# D1.pdf register map
Vendor: Allwinner; Series: D1.pdf; File version: 0.1
CPU: XuanTie C906 RISC-V CPU 0, little endian, MPU, FPU, double-precision FPU, 0 interrupt priority bits
Registers are 32-bit, read-write, reset 0x0 unless marked. A register's access mark holds for its fields unless they carry their own. Offsets are from the block's base; [hi:lo] are bit positions; {n}, {i} and the like mark numbered series; 'fields as' and 'values as' point back to an identical list.

## CCU (part 2 of 2)
Base 0x02001000
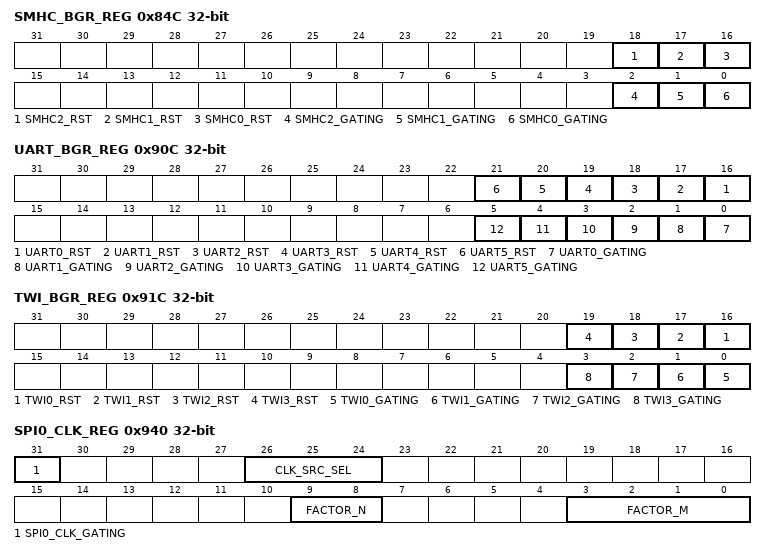
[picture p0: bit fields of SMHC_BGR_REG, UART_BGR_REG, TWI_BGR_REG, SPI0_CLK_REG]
0x84C SMHC_BGR_REG — SMHC Bus Gating Reset Register
  [18] SMHC2_RST — SMHC2 Reset 0: Assert 1: De-assert
    0=Assert; 1=deassert
  [17] SMHC1_RST — SMHC1 Reset 0: Assert 1: De-assert
    0=Assert; 1=deassert
  [16] SMHC0_RST — SMHC0 Reset 0: Assert 1: De-assert
    0=Assert; 1=deassert
  [2] SMHC2_GATING — Gating Clock for SMHC2 0: Mask 1: Pass
    0=Mask; 1=Pass
  [1] SMHC1_GATING — Gating Clock for SMHC1 0: Mask 1: Pass
    0=Mask; 1=Pass
  [0] SMHC0_GATING — Gating Clock for SMHC0 0: Mask 1: Pass
    0=Mask; 1=Pass
0x90C UART_BGR_REG — UART Bus Gating Reset Register
  [n+16] UART{n}_RST (n=0..5) — UART{n} Reset 0: Assert 1: De-assert
    0=Assert; 1=deassert
  [n] UART{n}_GATING (n=0..5) — Gating Clock for UART{n} 0: Mask 1: Pass
    0=Mask; 1=Pass
0x91C TWI_BGR_REG — TWI Bus Gating Reset Register
  [n+16] TWI{n}_RST (n=0..3) — TWI{n} Reset 0: Assert 1: De-assert
    0=Assert; 1=deassert
  [n] TWI{n}_GATING (n=0..3) — Gating Clock for TWI{n} 0: Mask 1: Pass
    0=Mask; 1=Pass
0x940 SPI0_CLK_REG — SPI0 Clock Register
  [31] SPI0_CLK_GATING — Gating Clock 0: Clock is OFF 1: Clock is ON SCLK = Clock Source/M/N.
    0=OFF (Clock is OFF); 1=ON (Clock is ON SCLK = Clock Source/M/N.)
  [26:24] CLK_SRC_SEL — Clock Source Select 000: HOSC 001: PLL_PERI(1X) 010: PLL_PERI(2X) 011: PLL_AUDIO1(DIV2) 100: PLL_AUDIO1(DIV5) Others: Reserved
    0=HOSC; 1=PLL_PERI_openingparen_1X_closingparen_ (PLL_PERI(1X)); 2=PLL_PERI_openingparen_2X_closingparen_ (PLL_PERI(2X)); 3=PLL_AUDIO1_openingparen_DIV2_closingparen_ (PLL_AUDIO1(DIV2)); 4=PLL_AUDIO1_openingparen_DIV5_closingparen_ (PLL_AUDIO1(DIV5))
  [9:8] FACTOR_N — Factor N 00: 1 01: 2 10: 4 11: 8
    0=_1; 1=_2; 2=_4; 3=_8
  [3:0] FACTOR_M — Factor M M= FACTOR_M +1 FACTOR_M is from 0 to 15.
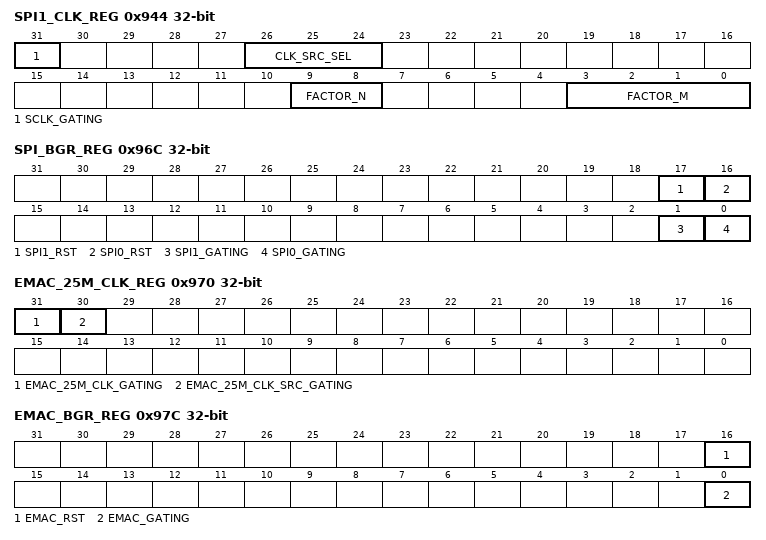
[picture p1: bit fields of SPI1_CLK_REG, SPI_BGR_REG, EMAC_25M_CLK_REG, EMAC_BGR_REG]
0x944 SPI1_CLK_REG — SPI1 Clock Register
  [31] SCLK_GATING — Gating Special Clock 0: Clock is OFF 1: Clock is ON SCLK = Clock Source/M/N.
    values as SPI0_CLK_REG.SPI0_CLK_GATING
  [26:24] CLK_SRC_SEL — Clock Source Select 000: HOSC 001: PLL_PERI(1X) 010: PLL_PERI(2X) 011: PLL_AUDIO1(DIV2) 100: PLL_AUDIO1(DIV5) Others: /
    values as SPI0_CLK_REG.CLK_SRC_SEL
  [9:8] FACTOR_N — Factor N 00: 1 01: 2 10: 4 11: 8
    0=_1; 1=_2; 2=_4; 3=_8
  [3:0] FACTOR_M — Factor M M= FACTOR_M +1 FACTOR_M is from 0 to 15.
0x96C SPI_BGR_REG — SPI Bus Gating Reset Register
  [17] SPI1_RST — SPI1 Reset 0: Assert 1: De-assert
    0=Assert; 1=deassert
  [16] SPI0_RST — SPI0 Reset 0: Assert 1: De-assert
    0=Assert; 1=deassert
  [1] SPI1_GATING — Gating Clock for SPI1 0: Mask 1: Pass
    0=Mask; 1=Pass
  [0] SPI0_GATING — Gating Clock for SPI0 0: Mask 1: Pass
    0=Mask; 1=Pass
0x970 EMAC_25M_CLK_REG — EMAC_25M Clock Register
  [31] EMAC_25M_CLK_GATING — Gating Special Clock 0: Clock is OFF 1: Clock is ON CLK = PLL_PERI(1X)/24 = 25 MHz
    0=OFF (Clock is OFF); 1=ON (Clock is ON CLK = PLL_PERI(1X)/24 = 25 MHz)
  [30] EMAC_25M_CLK_SRC_GATING — Gating the Source Clock of Special Clock It is for low power design. 0: Clock is OFF 1: Clock is ON
    0=OFF (Clock is OFF); 1=ON (Clock is ON)
0x97C EMAC_BGR_REG — EMAC Bus Gating Reset Register
  [16] EMAC_RST — EMAC Reset 0: Assert 1: De-assert
    0=Assert; 1=deassert
  [0] EMAC_GATING — Gating Clock for EMAC 0: Mask 1: Pass
    0=Mask; 1=Pass
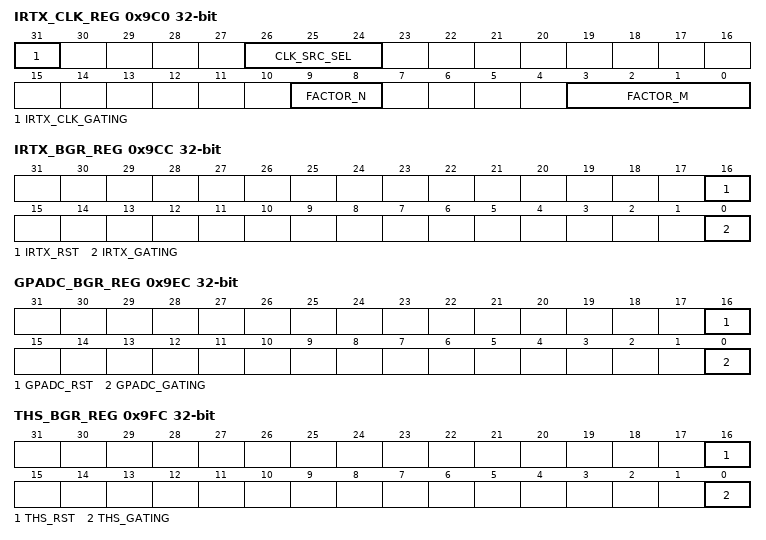
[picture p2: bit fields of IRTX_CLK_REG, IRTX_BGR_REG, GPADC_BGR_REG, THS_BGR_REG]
0x9C0 IRTX_CLK_REG — IRTX Clock Register
  [31] IRTX_CLK_GATING — Gating Clock 0: Clock is OFF 1: Clock is ON IRTX_CLK = Clock Source/M/N.
    0=OFF (Clock is OFF); 1=ON (Clock is ON IRTX_CLK = Clock Source/M/N.)
  [26:24] CLK_SRC_SEL — Clock Source Select 0: HOSC 1: PLL_PERI(1X)
  [9:8] FACTOR_N — Factor N 00: 1 01: 2 10: 4 11: 8
    0=_1; 1=_2; 2=_4; 3=_8
  [3:0] FACTOR_M — Factor M M= FACTOR_M +1 FACTOR_M is from 0 to 15.
0x9CC IRTX_BGR_REG — IRTX Bus Gating Reset Register
  [16] IRTX_RST — IRTX Reset 0: Assert 1: De-assert
    0=Assert; 1=deassert
  [0] IRTX_GATING — Gating Clock for IRTX 0: Mask 1: Pass
    0=Mask; 1=Pass
0x9EC GPADC_BGR_REG — GPADC Bus Gating Reset Register
  [16] GPADC_RST — GPADC Reset 0: Assert 1: De-assert
    0=Assert; 1=deassert
  [0] GPADC_GATING — Gating Clock for GPADC 0: Mask 1: Pass
    0=Mask; 1=Pass
0x9FC THS_BGR_REG — THS Bus Gating Reset Register
  [16] THS_RST — THS Reset 0: Assert 1: De-assert
    0=Assert; 1=deassert
  [0] THS_GATING — Gating Clock for THS 0: Mask 1: Pass
    0=Mask; 1=Pass
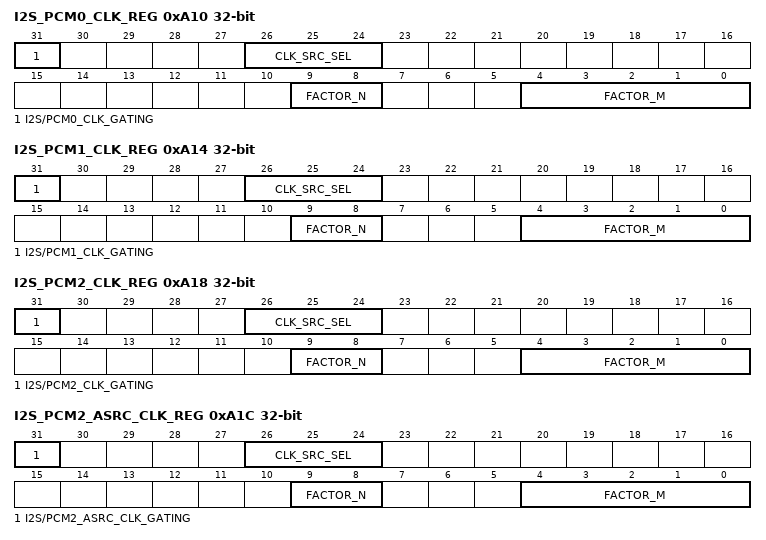
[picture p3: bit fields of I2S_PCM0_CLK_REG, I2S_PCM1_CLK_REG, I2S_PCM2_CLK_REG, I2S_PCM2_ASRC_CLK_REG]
0xA10 I2S_PCM0_CLK_REG
  [31] I2S/PCM0_CLK_GATING — Gating Clock 0: Clock is OFF 1: Clock is ON I2S/PCM0_CLK = Clock Source/M/N.
    0=OFF (Clock is OFF); 1=ON (Clock is ON I2S/PCM0_CLK = Clock Source/M/N.)
  [26:24] CLK_SRC_SEL — Clock Source Select 00: PLL_AUDIO0(1X) 01: PLL_AUDIO0(4X) 10: PLL_AUDIO1(DIV2) 11: PLL_AUDIO1(DIV5)
  [9:8] FACTOR_N — Factor N 00: /1 01: /2 10: /4 11: /8
    0=_slash_1 (/1); 1=_slash_2 (/2); 2=_slash_4 (/4); 3=_slash_8 (/8)
  [4:0] FACTOR_M — Factor M M= FACTOR_M +1 The value of FACTOR_M is from 0 to 31.
0xA14 I2S_PCM1_CLK_REG
  [31] I2S/PCM1_CLK_GATING — Gating Clock 0: Clock is OFF 1: Clock is ON I2S/PCM1_CLK = Clock Source/M/N.
    0=OFF (Clock is OFF); 1=ON (Clock is ON I2S/PCM1_CLK = Clock Source/M/N.)
  [26:24] CLK_SRC_SEL — Clock Source Select 00: PLL_AUDIO0(1X) 01: PLL_AUDIO0(4X) 10: PLL_AUDIO1(DIV2) 11: PLL_AUDIO1(DIV5)
  [9:8] FACTOR_N — Factor N 00: /1 01: /2 10: /4 11: /8
    values as I2S_PCM0_CLK_REG.FACTOR_N
  [4:0] FACTOR_M — Factor M M= FACTOR_M +1 FACTOR_M is from 0 to 31.
0xA18 I2S_PCM2_CLK_REG
  [31] I2S/PCM2_CLK_GATING — Gating Clock 0: Clock is OFF 1: Clock is ON I2S/PCM2_CLK = Clock Source/M/N.
    0=OFF (Clock is OFF); 1=ON (Clock is ON I2S/PCM2_CLK = Clock Source/M/N.)
  [26:24] CLK_SRC_SEL — Clock Source Select 00: PLL_AUDIO0(1X) 01: PLL_AUDIO0(4X) 10: PLL_AUDIO1(DIV2) 11: PLL_AUDIO1(DIV5)
  [9:8] FACTOR_N — Factor N 00: /1 01: /2 10: /4 11: /8
    values as I2S_PCM0_CLK_REG.FACTOR_N
  [4:0] FACTOR_M — Factor M M= FACTOR_M +1 FACTOR_M is from 0 to 31.
0xA1C I2S_PCM2_ASRC_CLK_REG
  [31] I2S/PCM2_ASRC_CLK_GATING — Gating Clock 0: Clock is OFF 1: Clock is ON I2S/PCM2_ASRC_CLK = Clock Source/M/N.
    0=OFF (Clock is OFF); 1=ON (Clock is ON I2S/PCM2_ASRC_CLK = Clock Source/M/N.)
  [26:24] CLK_SRC_SEL — Clock Source Select 00: PLL_AUDIO0(4X) 01: PLL_PERI(1X) 10: PLL_AUDIO1(DIV2) 11: PLL_AUDIO1(DIV5)
  [9:8] FACTOR_N — Factor N 00: /1 01: /2 10: /4 11: /8
    values as I2S_PCM0_CLK_REG.FACTOR_N
  [4:0] FACTOR_M — Factor M M = FACTOR_M +1 FACTOR_M is from 0 to 31.
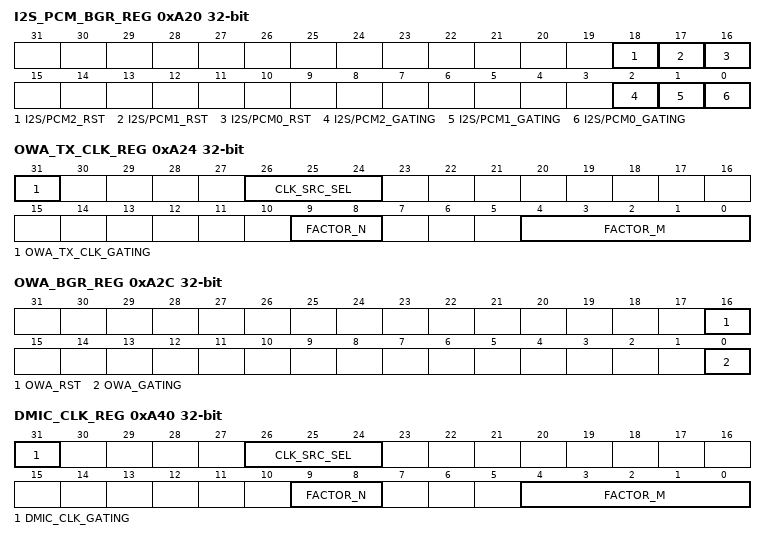
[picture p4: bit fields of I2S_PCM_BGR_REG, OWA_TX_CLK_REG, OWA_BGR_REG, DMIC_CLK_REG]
0xA20 I2S_PCM_BGR_REG
  [18] I2S/PCM2_RST — I2S/PCM2 Reset 0: Assert 1: De-assert
    0=Assert; 1=deassert
  [17] I2S/PCM1_RST — I2S/PCM1 Reset 0: Assert 1: De-assert
    0=Assert; 1=deassert
  [16] I2S/PCM0_RST — I2S/PCM0 Reset 0: Assert 1: De-assert
    0=Assert; 1=deassert
  [2] I2S/PCM2_GATING — Gating Clock for I2S/PCM2 0: Mask 1: Pass
    0=Mask; 1=Pass
  [1] I2S/PCM1_GATING — Gating Clock for I2S/PCM1 0: Mask 1: Pass
    0=Mask; 1=Pass
  [0] I2S/PCM0_GATING — Gating Clock for I2S/PCM0 0: Mask 1: Pass
    0=Mask; 1=Pass
0xA24 OWA_TX_CLK_REG — OWA_TX Clock Register
  [31] OWA_TX_CLK_GATING — Gating Clock 0: Clock is OFF 1: Clock is ON OWA_TX_CLK = Clock Source/M/N.
    0=OFF (Clock is OFF); 1=ON (Clock is ON OWA_TX_CLK = Clock Source/M/N.)
  [26:24] CLK_SRC_SEL — Clock Source Select 00: PLL_AUDIO0(1X) 01: PLL_AUDIO0(4X) 10: PLL_AUDIO1(DIV2) 11: PLL_AUDIO1(DIV5)
  [9:8] FACTOR_N — Factor N 00: /1 01: /2 10: /4 11: /8
    values as I2S_PCM0_CLK_REG.FACTOR_N
  [4:0] FACTOR_M — Factor M M= FACTOR_M +1 FACTOR_M is from 0 to 31.
0xA2C OWA_BGR_REG — OWA Bus Gating Reset Register
  [16] OWA_RST — OWA Reset 0: Assert 1: De-assert
    0=Assert; 1=deassert
  [0] OWA_GATING — Gating Clock for OWA 0: Mask 1: Pass
    0=Mask; 1=Pass
0xA40 DMIC_CLK_REG — DMIC Clock Register
  [31] DMIC_CLK_GATING — Gating Clock 0: Clock is OFF 1: Clock is ON DMIC_CLK = Clock Source/M/N.
    0=OFF (Clock is OFF); 1=ON (Clock is ON DMIC_CLK = Clock Source/M/N.)
  [26:24] CLK_SRC_SEL — Clock Source Select 00: PLL_AUDIO0(1X) 01: PLL_AUDIO1(DIV2) 10: PLL_AUDIO1(DIV5) 11: Reserved
  [9:8] FACTOR_N — Factor N 00: /1 01: /2 10: /4 11: /8
    values as I2S_PCM0_CLK_REG.FACTOR_N
  [4:0] FACTOR_M — Factor M M= FACTOR_M +1 FACTOR_M is from 0 to 31.
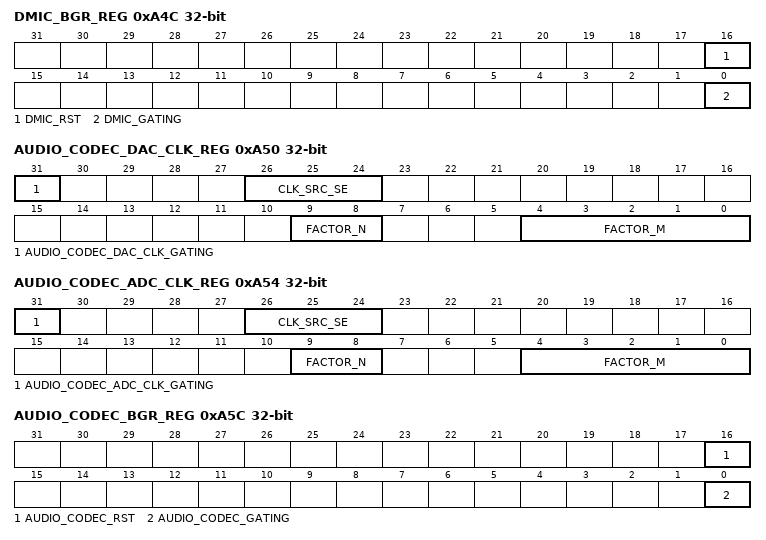
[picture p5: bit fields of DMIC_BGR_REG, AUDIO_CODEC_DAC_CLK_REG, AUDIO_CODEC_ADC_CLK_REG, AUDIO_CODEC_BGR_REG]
0xA4C DMIC_BGR_REG — DMIC Bus Gating Reset Register
  [16] DMIC_RST — DMIC Reset 0: Assert 1: De-assert
    0=Assert; 1=deassert
  [0] DMIC_GATING — Gating Clock for DMIC 0: Mask 1: Pass
    0=Mask; 1=Pass
0xA50 AUDIO_CODEC_DAC_CLK_REG — AUDIO_CODEC_DAC Clock Register
  [31] AUDIO_CODEC_DAC_CLK_GATING — Gating Clock 0: Clock is OFF 1: Clock is ON AUDIO_CODEC_DAC_CLK = Clock Source/M/N.
    0=OFF (Clock is OFF); 1=ON (Clock is ON AUDIO_CODEC_DAC_CLK = Clock Source/M/N.)
  [26:24] CLK_SRC_SE — Clock Source Select 00: PLL_AUDIO0(1X) 01: PLL_AUDIO1(DIV2) 10: PLL_AUDIO1(DIV5)
  [9:8] FACTOR_N — Factor N 00: /1 01: /2 10: /4 11: /8
    values as I2S_PCM0_CLK_REG.FACTOR_N
  [4:0] FACTOR_M — Factor M M= FACTOR_M +1 FACTOR_M is from 0 to 31.
0xA54 AUDIO_CODEC_ADC_CLK_REG — AUDIO_CODEC_ADC Clock Register
  [31] AUDIO_CODEC_ADC_CLK_GATING — Gating Clock 0: Clock is OFF 1: Clock is ON AUDIO_CODEC_ADC_CLK = Clock Source/M/N.
    0=OFF (Clock is OFF); 1=ON (Clock is ON AUDIO_CODEC_ADC_CLK = Clock Source/M/N.)
  [26:24] CLK_SRC_SE — Clock Source Select 00: PLL_AUDIO0(1X) 01: PLL_AUDIO1(DIV2) 10: PLL_AUDIO1(DIV5)
  [9:8] FACTOR_N — Factor N 00: /1 01: /2 10: /4 11: /8
    values as I2S_PCM0_CLK_REG.FACTOR_N
  [4:0] FACTOR_M — Factor M M= FACTOR_M +1 FACTOR_M is from 0 to 31.
0xA5C AUDIO_CODEC_BGR_REG — AUDIO_CODEC Bus Gating Reset Register
  [16] AUDIO_CODEC_RST — AUDIO_CODEC Reset 0: Assert 1: De-assert
    0=Assert; 1=deassert
  [0] AUDIO_CODEC_GATING — Gating Clock for AUDIO_CODEC 0: Mask 1: Pass
    0=Mask; 1=Pass
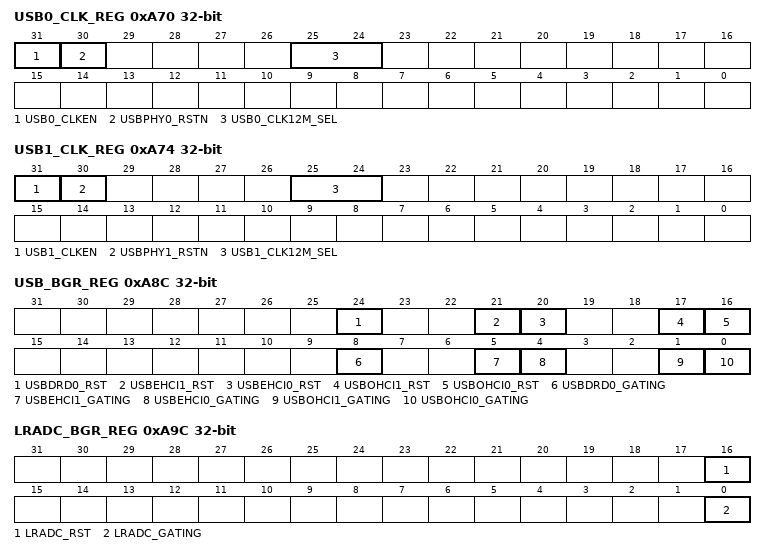
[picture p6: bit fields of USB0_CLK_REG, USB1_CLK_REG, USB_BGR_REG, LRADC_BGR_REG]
0xA70 USB0_CLK_REG — USB0 Clock Register
  [31] USB0_CLKEN — Gating Special Clock for OHCI0 0: Clock is OFF 1: Clock is ON
    0=OFF (Clock is OFF); 1=ON (Clock is ON)
  [30] USBPHY0_RSTN — USB PHY0 Reset 0: Assert 1: De-assert
    0=Assert; 1=deassert
  [25:24] USB0_CLK12M_SEL — OHCI0 12M Source Select 00: 12M divided from 48 MHz 01: 12M divided from 24 MHz 10: RTC_32K 11: /
0xA74 USB1_CLK_REG — USB1 Clock Register
  [31] USB1_CLKEN — Gating Special Clock for OHCI1 0: Clock is OFF 1: Clock is ON
    0=OFF (Clock is OFF); 1=ON (Clock is ON)
  [30] USBPHY1_RSTN — USB PHY1 Reset 0: Assert 1: De-assert
    0=Assert; 1=deassert
  [25:24] USB1_CLK12M_SEL — OHCI0 12M Source Select 00: 12M divided from 48 MHz 01: 12M divided from 24 MHz 10: RTC_32K 11: /
0xA8C USB_BGR_REG — USB Bus Gating Reset Register
  [24] USBDRD0_RST — USBDRD0 Reset 0: Assert 1: De-assert
    0=Assert; 1=deassert
  [21] USBEHCI1_RST — USBEHCI1 Reset 0: Assert 1: De-assert
    0=Assert; 1=deassert
  [20] USBEHCI0_RST — USBEHCI0 Reset 0: Assert 1: De-assert
    0=Assert; 1=deassert
  [17] USBOHCI1_RST — USBOHCI1 Reset 0: Assert 1: De-assert
    0=Assert; 1=deassert
  [16] USBOHCI0_RST — USBOHCI0 Reset 0: Assert 1: De-assert
    0=Assert; 1=deassert
  [8] USBDRD0_GATING — Gating Clock for USBDRD0 0: Mask 1: Pass
    0=Mask; 1=Pass
  [5] USBEHCI1_GATING — Gating Clock for USBEHCI1 0: Mask 1: Pass
    0=Mask; 1=Pass
  [4] USBEHCI0_GATING — Gating Clock for USBEHCI0 0: Mask 1: Pass
    0=Mask; 1=Pass
  [1] USBOHCI1_GATING — Gating Clock for USBOHCI1 0: Mask 1: Pass
    0=Mask; 1=Pass
  [0] USBOHCI0_GATING — Gating Clock for USBOHCI0 0: Mask 1: Pass
    0=Mask; 1=Pass
0xA9C LRADC_BGR_REG
  [16] LRADC_RST — LRADC Reset 0: Assert 1: De-assert
    0=Assert; 1=deassert
  [0] LRADC_GATING — Gating Clock for LRADC 0: Mask 1: Pass
    0=Mask; 1=Pass
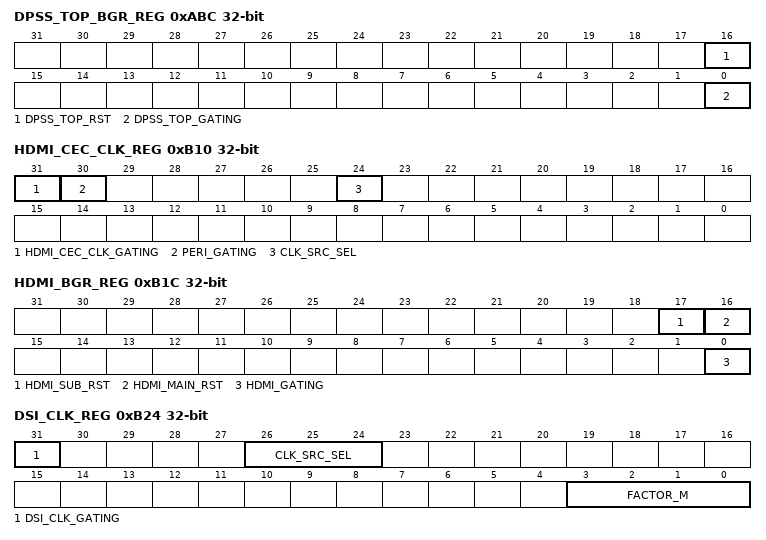
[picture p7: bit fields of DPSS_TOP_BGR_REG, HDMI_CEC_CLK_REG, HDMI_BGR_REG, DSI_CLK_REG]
0xABC DPSS_TOP_BGR_REG — DPSS_TOP Bus Gating Reset Register
  [16] DPSS_TOP_RST — DPSS_TOP Reset 0: Assert 1: De-assert
    0=Assert; 1=deassert
  [0] DPSS_TOP_GATING — Gating Clock for DPSS_TOP 0: Mask 1: Pass
    0=Mask; 1=Pass
0xB04 HDMI_24M_CLK_REG — HDMI_24M Clock Register
  [31] HDMI_24M_CLK_GATING — Gating Clock 0: Clock is OFF 1: Clock is ON HDMI_24M_CLK = HOSC
    0=OFF (Clock is OFF); 1=ON (Clock is ON HDMI_24M_CLK = HOSC)
0xB10 HDMI_CEC_CLK_REG — HDMI CEC Clock Register
  [31] HDMI_CEC_CLK_GATING — Gating Clock 0: Clock is OFF 1: Clock is ON HDMI_CEC_CLK = Clock Source.
    0=OFF (Clock is OFF); 1=ON (Clock is ON HDMI_CEC_CLK = Clock Source.)
  [30] PERI_GATING — Gating PERIPLL Clock 0: Clock is OFF 1: Clock is ON
    0=OFF (Clock is OFF); 1=ON (Clock is ON)
  [24] CLK_SRC_SEL — Clock Source Select 0: CLK32K 1: HDMI_CEC_CLK32K, PLL_PERI(2X)/36621 = 32.768 kHz 1X:/
    0=CLK32K; 1=HDMI_CEC_CLK32K (HDMI_CEC_CLK32K, PLL_PERI(2X)/36621 = 32.768 kHz)
0xB1C HDMI_BGR_REG — HDMI Bus Gating Reset Register
  [17] HDMI_SUB_RST — HDMI_SUB Reset 0: Assert 1: De-assert
    0=Assert; 1=deassert
  [16] HDMI_MAIN_RST — HDMI_MAIN Reset 0: Assert 1: De-assert
    0=Assert; 1=deassert
  [0] HDMI_GATING — Gating Clock for HDMI 0: Mask 1: Pass
    0=Mask; 1=Pass
0xB24 DSI_CLK_REG — DSI Clock Register
  [31] DSI_CLK_GATING — Gating Clock 0: Clock is OFF 1: Clock is ON DSI_CLK = Clock Source/M.
    0=OFF (Clock is OFF); 1=ON (Clock is ON DSI_CLK = Clock Source/M.)
  [26:24] CLK_SRC_SEL — Clock Source Select 000: HOSC 001: PLL_PERI(1X) 010: PLL_VIDEO0(2X) 011: PLL_VIDEO1(2X) 100: PLL_AUDIO1(DIV2)
    0=HOSC; 1=PLL_PERI_openingparen_1X_closingparen_ (PLL_PERI(1X)); 2=PLL_VIDEO0_openingparen_2X_closingparen_ (PLL_VIDEO0(2X)); 3=PLL_VIDEO1_openingparen_2X_closingparen_ (PLL_VIDEO1(2X)); 4=PLL_AUDIO1_openingparen_DIV2_closingparen_ (PLL_AUDIO1(DIV2))
  [3:0] FACTOR_M — Factor M M= FACTOR_M +1 FACTOR_M is from 0 to 15.
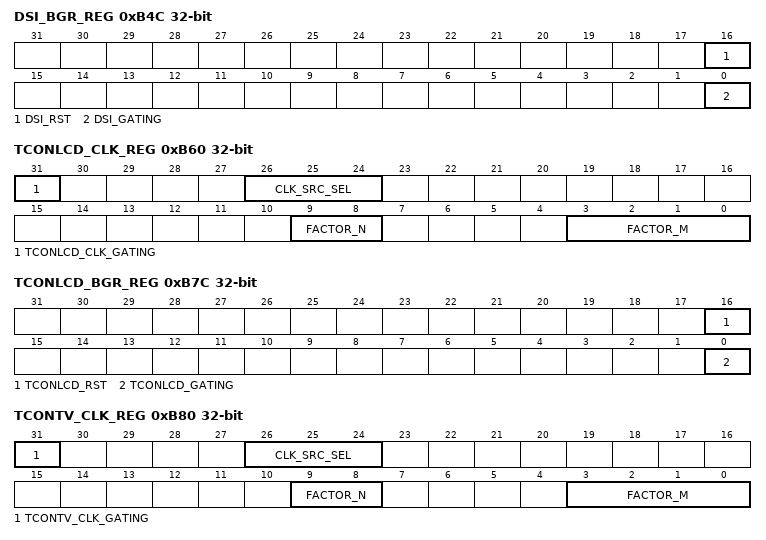
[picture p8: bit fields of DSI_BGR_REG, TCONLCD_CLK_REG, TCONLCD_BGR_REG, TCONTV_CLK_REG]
0xB4C DSI_BGR_REG — DSI Bus Gating Reset Register
  [16] DSI_RST — DSI Reset 0: Assert 1: De-assert
    0=Assert; 1=deassert
  [0] DSI_GATING — Gating Clock for DSI 0: Mask 1: Pass
    0=Mask; 1=Pass
0xB60 TCONLCD_CLK_REG — TCONLCD Clock Register
  [31] TCONLCD_CLK_GATING — Gating Clock 0: Clock is OFF 1: Clock is ON TCONLCD_CLK = Clock Source/M/N.
    0=OFF (Clock is OFF); 1=ON (Clock is ON TCONLCD_CLK = Clock Source/M/N.)
  [26:24] CLK_SRC_SEL — Clock Source Select 000: PLL_VIDEO0(1X) 001: PLL_VIDEO0(4X) 010: PLL_VIDEO1(1X) 011: PLL_VIDEO1(4X) 100: PLL_PERI(2X) 101: PLL_AUDIO1(DIV2)
    0=PLL_VIDEO0_openingparen_1X_closingparen_ (PLL_VIDEO0(1X)); 1=PLL_VIDEO0_openingparen_4X_closingparen_ (PLL_VIDEO0(4X)); 2=PLL_VIDEO1_openingparen_1X_closingparen_ (PLL_VIDEO1(1X)); 3=PLL_VIDEO1_openingparen_4X_closingparen_ (PLL_VIDEO1(4X)); 4=PLL_PERI_openingparen_2X_closingparen_ (PLL_PERI(2X)); 5=PLL_AUDIO1_openingparen_DIV2_closingparen_ (PLL_AUDIO1(DIV2))
  [9:8] FACTOR_N — Factor N 00: 1 01: 2 10: 4 11: 8
    0=_1; 1=_2; 2=_4; 3=_8
  [3:0] FACTOR_M — Factor M M= FACTOR_M +1. FACTOR_M is from 0 to 15.
0xB7C TCONLCD_BGR_REG — TCONLCD Bus Gating Reset Register
  [16] TCONLCD_RST — TCON LCD Reset 0: Assert 1: DE-assert
    0=Assert; 1=deassert
  [0] TCONLCD_GATING — Gating Clock for TCON LCD 0: Mask 1: Pass
    0=Mask; 1=Pass
0xB80 TCONTV_CLK_REG — TCONTV Clock Register
  [31] TCONTV_CLK_GATING — Gating Clock 0: Clock is OFF 1: Clock is ON TCONTV_CLK = Clock Source/M/N.
    0=OFF (Clock is OFF); 1=ON (Clock is ON TCONTV_CLK = Clock Source/M/N.)
  [26:24] CLK_SRC_SEL — Clock Source Select 000: PLL_VIDEO0(1X) 001: PLL_VIDEO0(4X) 010: PLL_VIDEO1(1X) 011: PLL_VIDEO1(4X) 100: PLL_PERI(2X) 101: PLL_AUDIO1(DIV2)
    values as TCONLCD_CLK_REG.CLK_SRC_SEL
  [9:8] FACTOR_N — Factor N 00: 1 01: 2 10: 4 11: 8
    0=_1; 1=_2; 2=_4; 3=_8
  [3:0] FACTOR_M — Factor M M= FACTOR_M +1 FACTOR_M is from 0 to 15.
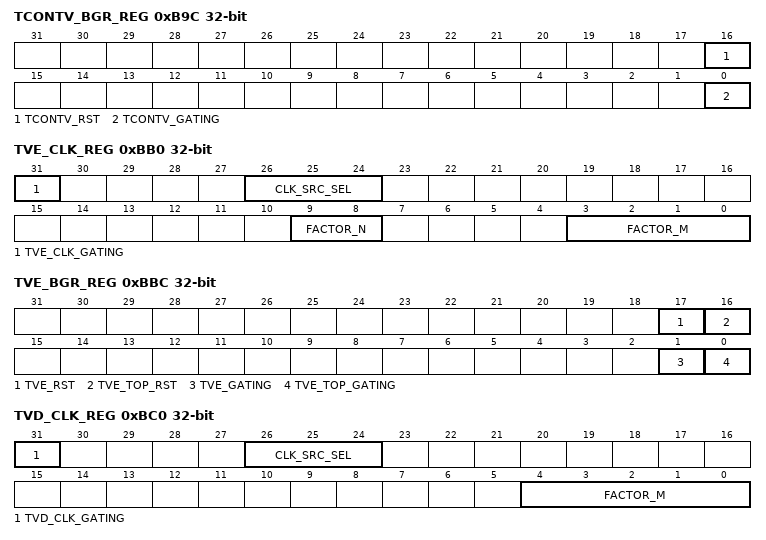
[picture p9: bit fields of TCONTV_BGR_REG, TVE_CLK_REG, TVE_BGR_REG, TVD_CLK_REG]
0xB9C TCONTV_BGR_REG — TCONTV Bus Gating Reset Register
  [16] TCONTV_RST — TCONTV Reset 0: Assert 1: De-assert
    0=Assert; 1=deassert
  [0] TCONTV_GATING — Gating Clock for TCONTV 0: Mask 1: Pass
    0=Mask; 1=Pass
0xBAC LVDS_BGR_REG — LVDS Bus Gating Reset Register
  [16] LVDS0_RST — LVDS0 Reset 0: Assert 1: De-assert
    0=Assert; 1=deassert
0xBB0 TVE_CLK_REG — TVE Clock Register
  [31] TVE_CLK_GATING — Gating Clock 0: Clock is OFF 1: Clock is ON TVE_CLK = Clock Source/M/N.
    0=OFF (Clock is OFF); 1=ON (Clock is ON TVE_CLK = Clock Source/M/N.)
  [26:24] CLK_SRC_SEL — Clock Source Select 000: PLL_VIDEO0(1X) 001: PLL_VIDEO0(4X) 010: PLL_VIDEO1(1X) 011: PLL_VIDEO1(4X) 100: PLL_PERI(2X) 101: PLL_AUDIO1(DIV2)
    values as TCONLCD_CLK_REG.CLK_SRC_SEL
  [9:8] FACTOR_N — Factor N 00: 1 01: 2 10: 4 11: 8
    0=_1; 1=_2; 2=_4; 3=_8
  [3:0] FACTOR_M — Factor M M= FACTOR_M +1 FACTOR_M is from 0 to 15.
0xBBC TVE_BGR_REG — TVE Bus Gating Reset Register
  [17] TVE_RST — TVE Reset 0: Assert 1: De-assert
    0=Assert; 1=deassert
  [16] TVE_TOP_RST — TVE_TOP Reset 0: Assert 1: De-assert
    0=Assert; 1=deassert
  [1] TVE_GATING — Gating Clock for TVE 0: Mask 1: Pass
    0=Mask; 1=Pass
  [0] TVE_TOP_GATING — Gating Clock for TVE_TOP 0: Mask 1: Pass
    0=Mask; 1=Pass
0xBC0 TVD_CLK_REG — TVD Clock Register
  [31] TVD_CLK_GATING — Gating Special Clock 0: Clock is OFF 1: Clock is ON TVD_CLK = Clock Source/M.
    0=OFF (Clock is OFF); 1=ON (Clock is ON TVD_CLK = Clock Source/M.)
  [26:24] CLK_SRC_SEL — Clock Source Select 000: HOSC 001: PLL_VIDEO0(1X) 010: PLL_VIDEO1(1X) 011: PLL_PERI(1X)
    0=HOSC; 1=PLL_VIDEO0_openingparen_1X_closingparen_ (PLL_VIDEO0(1X)); 2=PLL_VIDEO1_openingparen_1X_closingparen_ (PLL_VIDEO1(1X)); 3=PLL_PERI_openingparen_1X_closingparen_ (PLL_PERI(1X))
  [4:0] FACTOR_M — Factor M M= FACTOR_M +1 FACTOR_M is from 0 to 31.
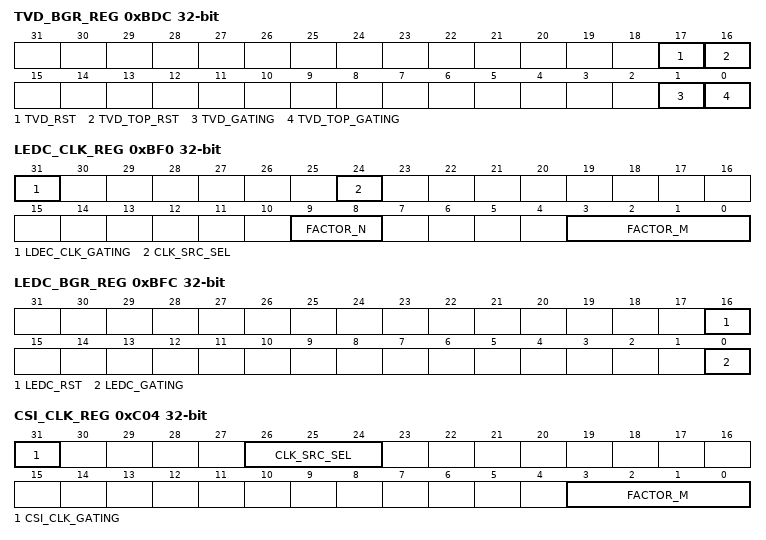
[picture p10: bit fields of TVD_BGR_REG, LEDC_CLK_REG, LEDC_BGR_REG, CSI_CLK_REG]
0xBDC TVD_BGR_REG — TVD Bus Gating Reset Register
  [17] TVD_RST — TVD Reset 0: Assert 1: De-assert
    0=Assert; 1=deassert
  [16] TVD_TOP_RST — TVD_TOP Reset 0: Assert 1: De-assert
    0=Assert; 1=deassert
  [1] TVD_GATING — Gating Clock for TVD 0: Mask 1: Pass
    0=Mask; 1=Pass
  [0] TVD_TOP_GATING — Gating Clock for TVD_TOP 0: Mask 1: Pass
    0=Mask; 1=Pass
0xBF0 LEDC_CLK_REG — LEDC Clock Register
  [31] LDEC_CLK_GATING — Gating Clock 0: Clock is OFF 1: Clock is ON LEDC_CLK = Clock Source/M/N.
    0=OFF (Clock is OFF); 1=ON (Clock is ON LEDC_CLK = Clock Source/M/N.)
  [24] CLK_SRC_SEL — Clock Source Select 0: HOSC 1: PLL_PERI(1X)
    0=HOSC; 1=PLL_PERI_openingparen_1X_closingparen_ (PLL_PERI(1X))
  [9:8] FACTOR_N — Factor N 00: 1 01: 2 10: 4 11: 8
    0=_1; 1=_2; 2=_4; 3=_8
  [3:0] FACTOR_M — Factor M M= FACTOR_M +1 FACTOR_M is from 0 to 15.
0xBFC LEDC_BGR_REG — LEDC Bus Gating Reset Register
  [16] LEDC_RST — LEDC Reset 0: Assert 1: De-assert
    0=Assert; 1=deassert
  [0] LEDC_GATING — Gating Clock for LEDC 0: Mask 1: Pass
    0=Mask; 1=Pass
0xC04 CSI_CLK_REG — CSI Clock Register
  [31] CSI_CLK_GATING — Gating Clock 0: Clock is OFF 1: Clock is ON CSI_CLK = Clock Source/M.
    0=OFF (Clock is OFF); 1=ON (Clock is ON CSI_CLK = Clock Source/M.)
  [26:24] CLK_SRC_SEL — Clock Source Select 000: PLL_PERI(2X) 001: PLL_VIDEO0(2X) 010: PLL_VIDEO1(2X)
    0=PLL_PERI_openingparen_2X_closingparen_ (PLL_PERI(2X)); 1=PLL_VIDEO0_openingparen_2X_closingparen_ (PLL_VIDEO0(2X)); 2=PLL_VIDEO1_openingparen_2X_closingparen_ (PLL_VIDEO1(2X))
  [3:0] FACTOR_M — Factor M M= FACTOR_M +1 FACTOR_M is from 0 to 15.
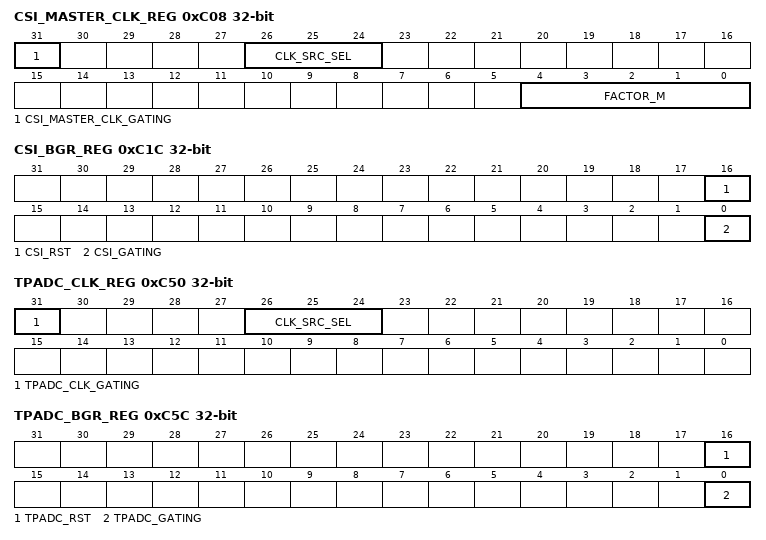
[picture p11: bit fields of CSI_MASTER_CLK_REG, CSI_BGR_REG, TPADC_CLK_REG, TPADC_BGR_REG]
0xC08 CSI_MASTER_CLK_REG — CSI Master Clock Register
  [31] CSI_MASTER_CLK_GATING — Gating Clock 0: Clock is OFF 1: Clock is ON CSI_MASTER_CLK = Clock Source/M.
    0=OFF (Clock is OFF); 1=ON (Clock is ON CSI_MASTER_CLK = Clock Source/M.)
  [26:24] CLK_SRC_SEL — Clock Source Select 000: HOSC 001: PLL_PERI(1X) 010: PLL_VIDEO0(1X) 011: PLL_VIDEO1(1X) 100: PLL_AUDIO1(DIV2) 101: PLL_AUDIO1(DIV5)
    0=HOSC; 1=PLL_PERI_openingparen_1X_closingparen_ (PLL_PERI(1X)); 2=PLL_VIDEO0_openingparen_1X_closingparen_ (PLL_VIDEO0(1X)); 3=PLL_VIDEO1_openingparen_1X_closingparen_ (PLL_VIDEO1(1X)); 4=PLL_AUDIO1_openingparen_DIV2_closingparen_ (PLL_AUDIO1(DIV2)); 5=PLL_AUDIO1_openingparen_DIV5_closingparen_ (PLL_AUDIO1(DIV5))
  [4:0] FACTOR_M — Factor M M= FACTOR_M +1 FACTOR_M is from 0 to 31.
0xC1C CSI_BGR_REG — CSI Bus Gating Reset Register
  [16] CSI_RST — CSI Reset 0: Assert 1: De-assert
    0=Assert; 1=deassert
  [0] CSI_GATING — Gating Clock for CSI 0: Mask 1: Pass
    0=Mask; 1=Pass
0xC50 TPADC_CLK_REG — TPADC Clock Register
  [31] TPADC_CLK_GATING — Gating Clock 0: Clock is OFF 1: Clock is ON TPADC_CLK = Clock Source.
    0=OFF (Clock is OFF); 1=ON (Clock is ON TPADC_CLK = Clock Source.)
  [26:24] CLK_SRC_SEL — Clock Source Select 000: HOSC 001: PLL_AUDIO0(1X)
    0=HOSC; 1=PLL_AUDIO0_openingparen_1X_closingparen_ (PLL_AUDIO0(1X))
0xC5C TPADC_BGR_REG — TPADC Bus Gating Reset Register
  [16] TPADC_RST — TPADC Reset 0: Assert 1: De-assert
    0=Assert; 1=deassert
  [0] TPADC_GATING — Gating Clock for TPADC 0: Mask 1: Pass
    0=Mask; 1=Pass
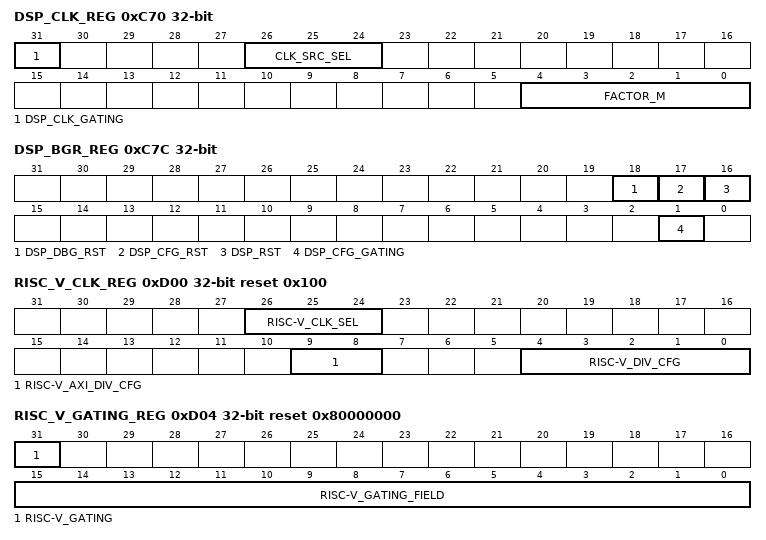
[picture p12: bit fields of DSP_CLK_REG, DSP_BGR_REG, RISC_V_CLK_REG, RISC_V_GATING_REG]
0xC70 DSP_CLK_REG — DSP Clock Register
  [31] DSP_CLK_GATING — Gating Clock 0: Clock is OFF 1: Clock is ON DSP_CLK = Clock Source/M.
    0=OFF (Clock is OFF); 1=ON (Clock is ON DSP_CLK = Clock Source/M.)
  [26:24] CLK_SRC_SEL — Clock Source Select 000: HOSC 001: CLK32K 010: CLK16M_RC 011: PLL_PERI(2X) 100: PLL_AUDIO1(DIV2)
    0=HOSC; 1=CLK32K; 2=CLK16M_RC; 3=PLL_PERI_openingparen_2X_closingparen_ (PLL_PERI(2X)); 4=PLL_AUDIO1_openingparen_DIV2_closingparen_ (PLL_AUDIO1(DIV2))
  [4:0] FACTOR_M — Factor M M= FACTOR_M +1 FACTOR_M is from 0 to 31.
0xC7C DSP_BGR_REG — DSP Bus Gating Reset Register
  [18] DSP_DBG_RST — DSP_DBG Reset 0: Assert 1: De-assert
    0=Assert; 1=deassert
  [17] DSP_CFG_RST — DSP_CFG Reset 0: Assert 1: De-assert
    0=Assert; 1=deassert
  [16] DSP_RST — DSP Reset 0: Assert 1: De-assert
    0=Assert; 1=deassert
  [1] DSP_CFG_GATING — Gating Clock for DSP_CFG 0: Mask 1: Pass
    0=Mask; 1=Pass
0xD00 RISC_V_CLK_REG reset 0x100
  [26:24] RISC-V_CLK_SEL — Clock Source Select 000: HOSC 001: CLK32K 010: CLK16M_RC 011: PLL_PERI(800M) 100: PLL_PERI(1X) 101: PLL_CPU 110: PLL_AUDIO1(DIV2) RISC-V Clock = Clock Source/M. RISC-V_AXI Clock = RISC-V Clock/N.
    0=HOSC; 1=CLK32K; 2=CLK16M_RC; 3=PLL_PERI_openingparen_800M_closingparen_ (PLL_PERI(800M)); 4=PLL_PERI_openingparen_1X_closingparen_ (PLL_PERI(1X)); 5=PLL_CPU; 6=PLL_AUDIO1_openingparen_DIV2_closingparen_ (PLL_AUDIO1(DIV2) RISC-V Clock = Clock Source/M. RISC-V_AXI Clock = RISC-V Clock/N.)
  [9:8] RISC-V_AXI_DIV_CFG — Factor N N = FACTOR_N +1 FACTOR_N is from 1 to 3.
  [4:0] RISC-V_DIV_CFG — Factor M M = FACTOR_M +1 FACTOR_M is from 0 to 31.
0xD04 RISC_V_GATING_REG reset 0x80000000
  [31] RISC-V_GATING — Gating Special Clock 0: Clock is OFF 1: Clock is ON
    0=OFF (Clock is OFF); 1=ON (Clock is ON)
  [15:0] RISC-V_GATING_FIELD wo — If RISC-V_gating_field == 16’h16AA, the bit 31 can be configured.
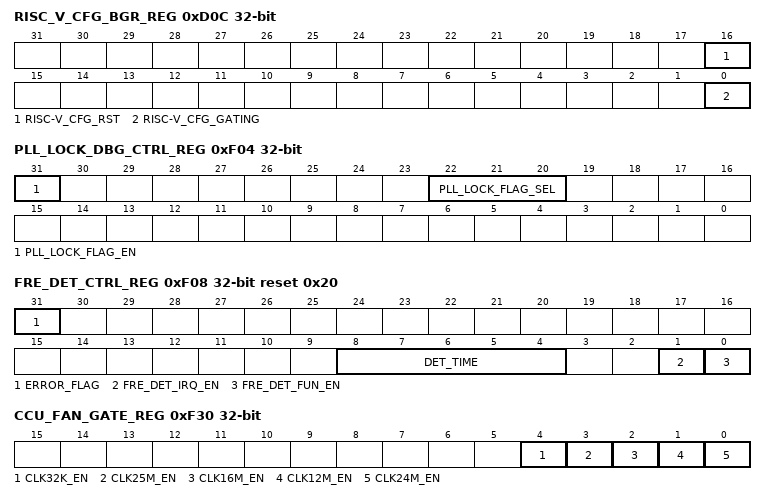
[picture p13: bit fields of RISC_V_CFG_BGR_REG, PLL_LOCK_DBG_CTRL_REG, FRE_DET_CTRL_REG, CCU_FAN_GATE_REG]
0xD0C RISC_V_CFG_BGR_REG
  [16] RISC-V_CFG_RST — RISC-V Reset 0: Assert 1: De-assert
    0=Assert; 1=deassert
  [0] RISC-V_CFG_GATING — Gating Clock for RISC-V 0: Mask 1: Pass
    0=Mask; 1=Pass
0xF04 PLL_LOCK_DBG_CTRL_REG — PLL Lock Debug Control Register
  [31] PLL_LOCK_FLAG_EN — Debug Enable 0: Disable 1: Enable
    0=Disable; 1=Enable
  [22:20] PLL_LOCK_FLAG_SEL — Debug Select 000: PLL_CPUX 001: PLL_DDR 010: PLL_PERI(2X) 011: PLL_VIDEO0(4X) 100: PLL_VIDEO1(4X) 101: PLL_VE 110: PLL_AUDIO0 111: PLL_AUDIO1 Others: /
    0=PLL_CPUX; 1=PLL_DDR; 2=PLL_PERI_openingparen_2X_closingparen_ (PLL_PERI(2X)); 3=PLL_VIDEO0_openingparen_4X_closingparen_ (PLL_VIDEO0(4X)); 4=PLL_VIDEO1_openingparen_4X_closingparen_ (PLL_VIDEO1(4X)); 5=PLL_VE; 6=PLL_AUDIO0; 7=PLL_AUDIO1
0xF08 FRE_DET_CTRL_REG reset 0x20 — Frequency Detect Control Register
  [31] ERROR_FLAG write-0-clears — Error Flag 0: Write 0 to clear 1: Error
    0=Write 0 to clear; 1=Error
  [8:4] DET_TIME — Detect Time Time=1/32k*(2^RegValue) RegValue is from 0 to 16.
  [1] FRE_DET_IRQ_EN — Frequence Detect IRQ Enable 0: Disable 1: Enable
    0=Disable; 1=Enable
  [0] FRE_DET_FUN_EN — Frequence Detect Function Enable 0: Disable 1: Enable
    0=Disable; 1=Enable
0xF0C FRE_UP_LIM_REG — Frequency Up Limit Register
  [31:0] FRE_UP_LIM — Frequence Up Limit
0xF10 FRE_DOWN_LIM_REG — Frequency Down Limit Register
  [31:0] FRE_DOWN_LIM — Frequence Down Limit
0xF30 CCU_FAN_GATE_REG — CCU FANOUT CLOCK GATE Register
  [all] fields
    0=OFF (Clock is OFF); 1=ON (Clock is ON)
  [4] CLK32K_EN — Gating for CLK32K 0: Clock is OFF 1: Clock is ON
  [3] CLK25M_EN — Gating for CLK25M 0: Clock is OFF 1: Clock is ON
  [2] CLK16M_EN — Gating for CLK16M 0: Clock is OFF 1: Clock is ON
  [1] CLK12M_EN — Gating for CLK12M 0: Clock is OFF 1: Clock is ON
  [0] CLK24M_EN — Gating for CLK24M 0: Clock is OFF 1: Clock is ON
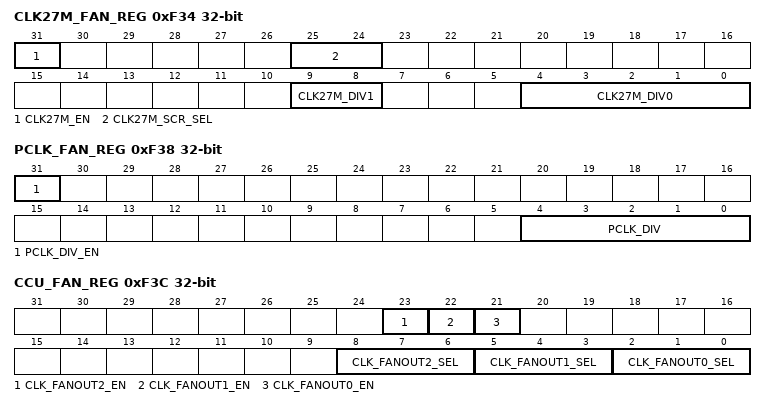
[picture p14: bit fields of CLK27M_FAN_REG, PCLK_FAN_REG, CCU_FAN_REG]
0xF34 CLK27M_FAN_REG — CLK27M FANOUT Register
  [31] CLK27M_EN — Gating for CLK27M 0: Clock is OFF 1: Clock is ON SCLK = Clock Source/M/N.
    values as SPI0_CLK_REG.SPI0_CLK_GATING
  [25:24] CLK27M_SCR_SEL — Clock Source Select 000: PLL_VIDEO0(1X) 001: PLL_VIDEO1(1X) 010: / 011: /
  [9:8] CLK27M_DIV1 — Factor N N= FACTOR_N +1. FACTOR_N is from 0 to 3.
  [4:0] CLK27M_DIV0 — Factor M M= FACTOR_M +1. FACTOR_M is from 0 to 31.
0xF38 PCLK_FAN_REG — PCLK FANOUT Register
  [31] PCLK_DIV_EN — Gating for PCLK 0: Clock is OFF 1: Clock is ON PCLK = APB0_CLK/M.
    0=OFF (Clock is OFF); 1=ON (Clock is ON PCLK = APB0_CLK/M.)
  [4:0] PCLK_DIV — Factor M M= FACTOR_M +1 FACTOR_M is from 0 to 31.
0xF3C CCU_FAN_REG — CCU FANOUT Register
  [23] CLK_FANOUT2_EN — Gating for CLK_FANOUT2 0: Clock is OFF 1: Clock is ON
    0=OFF (Clock is OFF); 1=ON (Clock is ON)
  [22] CLK_FANOUT1_EN — Gating for CLK_FANOUT1 0: Clock is OFF 1: Clock is ON
    0=OFF (Clock is OFF); 1=ON (Clock is ON)
  [21] CLK_FANOUT0_EN — Gating for CLK_FANOUT0 0: Clock is OFF 1: Clock is ON
    0=OFF (Clock is OFF); 1=ON (Clock is ON)
  [8:6] CLK_FANOUT2_SEL — 000: CLK32K (From PLL_PERI(2X)) 001: CLK12M (From DCXO/2) 010: CLK16M (From PLL_PERI(2X)) 011: CLK24M (From DCXO) 100: CLK25M (From PLL_PERI(1X)) 101: CLK27M 110: PCLK CLK_FANOUT2 can be selected to output from the above seven sources.
    0=CLK32K (CLK32K (From PLL_PERI(2X))); 1=CLK12M (CLK12M (From DCXO/2)); 2=CLK16M (CLK16M (From PLL_PERI(2X))); 3=CLK24M (CLK24M (From DCXO)); 4=CLK25M (CLK25M (From PLL_PERI(1X))); 5=CLK27M; 6=PCLK (PCLK CLK_FANOUT2 can be selected to output from the above seven sources.)
  [5:3] CLK_FANOUT1_SEL — 000: CLK32K (From PLL_PERI(2X)) 001: CLK12M (From DCXO/2) 010: CLK16M (From PLL_PERI(2X)) 011: CLK24M (From DCXO) 100: CLK25M (From PLL_PERI(1X)) 101: CLK27M 110: PCLK CLK_FANOUT1 can be selected to output from the above seven sources.
    0=CLK32K (CLK32K (From PLL_PERI(2X))); 1=CLK12M (CLK12M (From DCXO/2)); 2=CLK16M (CLK16M (From PLL_PERI(2X))); 3=CLK24M (CLK24M (From DCXO)); 4=CLK25M (CLK25M (From PLL_PERI(1X))); 5=CLK27M; 6=PCLK (PCLK CLK_FANOUT1 can be selected to output from the above seven sources.)
  [2:0] CLK_FANOUT0_SEL — 000: CLK32K (From PLL_PERI(2X)) 001: CLK12M (From DCXO) 010: CLK16M (From PLL_PERI(2X)) 011: CLK24M (From DCXO) 100: CLK25M (From PLL_PERI(1X)) 101: CLK27M 110: PCLK CLK_FANOUT0 can be selected to output from the above seven sources.
    0=CLK32K (CLK32K (From PLL_PERI(2X))); 1=CLK12M (CLK12M (From DCXO)); 2=CLK16M (CLK16M (From PLL_PERI(2X))); 3=CLK24M (CLK24M (From DCXO)); 4=CLK25M (CLK25M (From PLL_PERI(1X))); 5=CLK27M; 6=PCLK (PCLK CLK_FANOUT0 can be selected to output from the above seven sources.)
